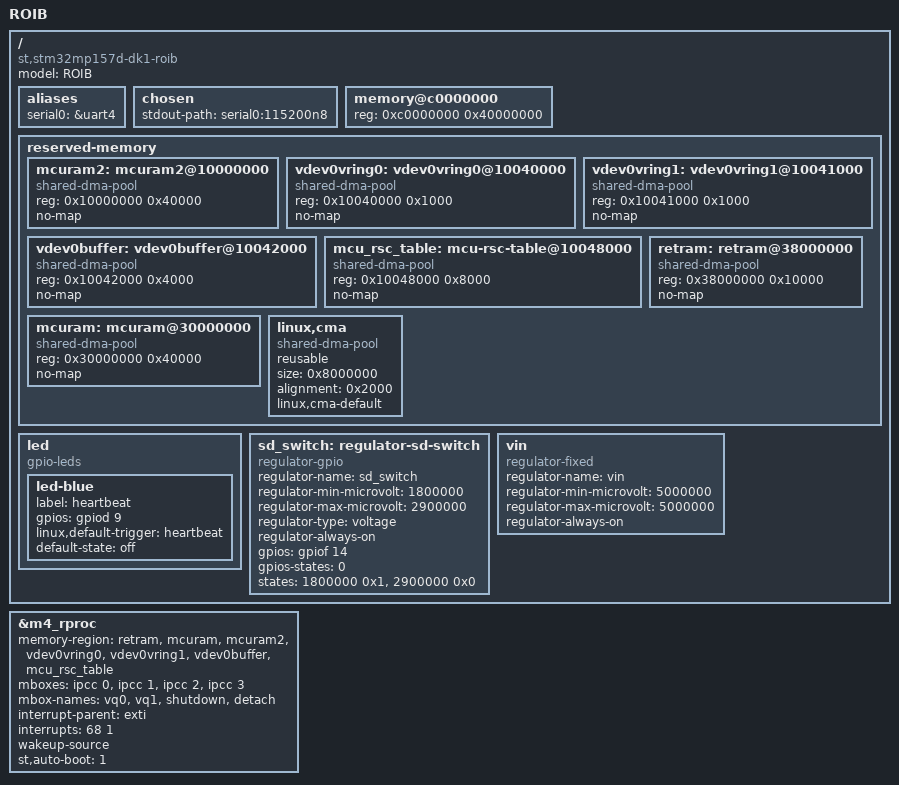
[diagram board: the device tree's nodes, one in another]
/dts-v1/;

#include "stm32mp157d-dk1.dts"
#include "stm32mp15-m4-srm.dtsi"
#include "stm32mp15-m4-srm-pinctrl.dtsi"

/ {
	model = "ROIB";
	compatible = "st,stm32mp157d-dk1-roib", "st,stm32mp157d-dk1", "st,stm32mp157";

	aliases {
		serial0 = &uart4;
	};

	chosen {
		stdout-path = "serial0:115200n8";
	};

	memory@c0000000 {
		device_type = "memory";
		reg = <0xc0000000 0x40000000>;
	};

	reserved-memory {
		#address-cells = <1>;
		#size-cells = <1>;
		ranges;

		mcuram2: mcuram2@10000000 {
			compatible = "shared-dma-pool";
			reg = <0x10000000 0x40000>;
			no-map;
		};

		vdev0vring0: vdev0vring0@10040000 {
			compatible = "shared-dma-pool";
			reg = <0x10040000 0x1000>;
			no-map;
		};

		vdev0vring1: vdev0vring1@10041000 {
			compatible = "shared-dma-pool";
			reg = <0x10041000 0x1000>;
			no-map;
		};

		vdev0buffer: vdev0buffer@10042000 {
			compatible = "shared-dma-pool";
			reg = <0x10042000 0x4000>;
			no-map;
		};

		mcu_rsc_table: mcu-rsc-table@10048000 {
			compatible = "shared-dma-pool";
			reg = <0x10048000 0x8000>;
			no-map;
		};

		mcuram: mcuram@30000000 {
			compatible = "shared-dma-pool";
			reg = <0x30000000 0x40000>;
			no-map;
		};

		retram: retram@38000000 {
			compatible = "shared-dma-pool";
			reg = <0x38000000 0x10000>;
			no-map;
		};


		/* global autoconfigured region for contiguous allocations */
		linux,cma {
			compatible = "shared-dma-pool";
			reusable;
			size = <0x8000000>;
			alignment = <0x2000>;
			linux,cma-default;
		};
	};

	led {
		compatible = "gpio-leds";
		led-blue {
			label = "heartbeat";
			gpios = <&gpiod 9 GPIO_ACTIVE_HIGH>;
			linux,default-trigger = "heartbeat";
			default-state = "off";
		};
	};

	sd_switch: regulator-sd-switch {
		compatible = "regulator-gpio";
		regulator-name = "sd_switch";
		regulator-min-microvolt = <1800000>;
		regulator-max-microvolt = <2900000>;
		regulator-type = "voltage";
		regulator-always-on;

		gpios = <&gpiof 14 GPIO_ACTIVE_HIGH>;
		gpios-states = <0>;
		states = <1800000 0x1>,
			 <2900000 0x0>;
	};

	vin: vin {
		compatible = "regulator-fixed";
		regulator-name = "vin";
		regulator-min-microvolt = <5000000>;
		regulator-max-microvolt = <5000000>;
		regulator-always-on;
	};
};

&m4_rproc {
	memory-region = <&retram>, <&mcuram>, <&mcuram2>, <&vdev0vring0>,
			<&vdev0vring1>, <&vdev0buffer>, <&mcu_rsc_table>;
	mboxes = <&ipcc 0>, <&ipcc 1>, <&ipcc 2>, <&ipcc 3>;
	mbox-names = "vq0", "vq1", "shutdown", "detach";
	interrupt-parent = <&exti>;
	interrupts = <68 1>;
	wakeup-source;
	status = "okay";
	st,auto-boot = <1>;
};
